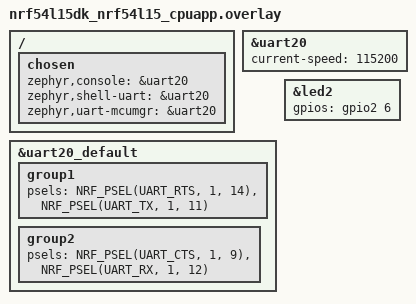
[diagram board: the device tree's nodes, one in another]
/* bl54l15_dvk_nrf54l15_cpuapp.overlay */

/ {
  chosen {
    zephyr,console = &uart20;
    zephyr,shell-uart = &uart20;
    zephyr,uart-mcumgr = &uart20;    /* Nếu dùng MCUmgr */
  };
};

&uart20 {
  status = "okay";
  current-speed = <115200>;
};

&uart20_default {
  group1 {
    psels = <NRF_PSEL(UART_RTS, 1, 14)>,
            <NRF_PSEL(UART_TX, 1, 11)>;
  };

  group2 {
    psels = <NRF_PSEL(UART_CTS, 1, 9)>,
            <NRF_PSEL(UART_RX, 1, 12)>;
  };
};
// &button0 {
//     gpios = <&gpio2 7 (GPIO_ACTIVE_LOW | GPIO_PULL_UP)>;
// };

&led2 {
  gpios = <&gpio2 6 GPIO_ACTIVE_HIGH>;
};
